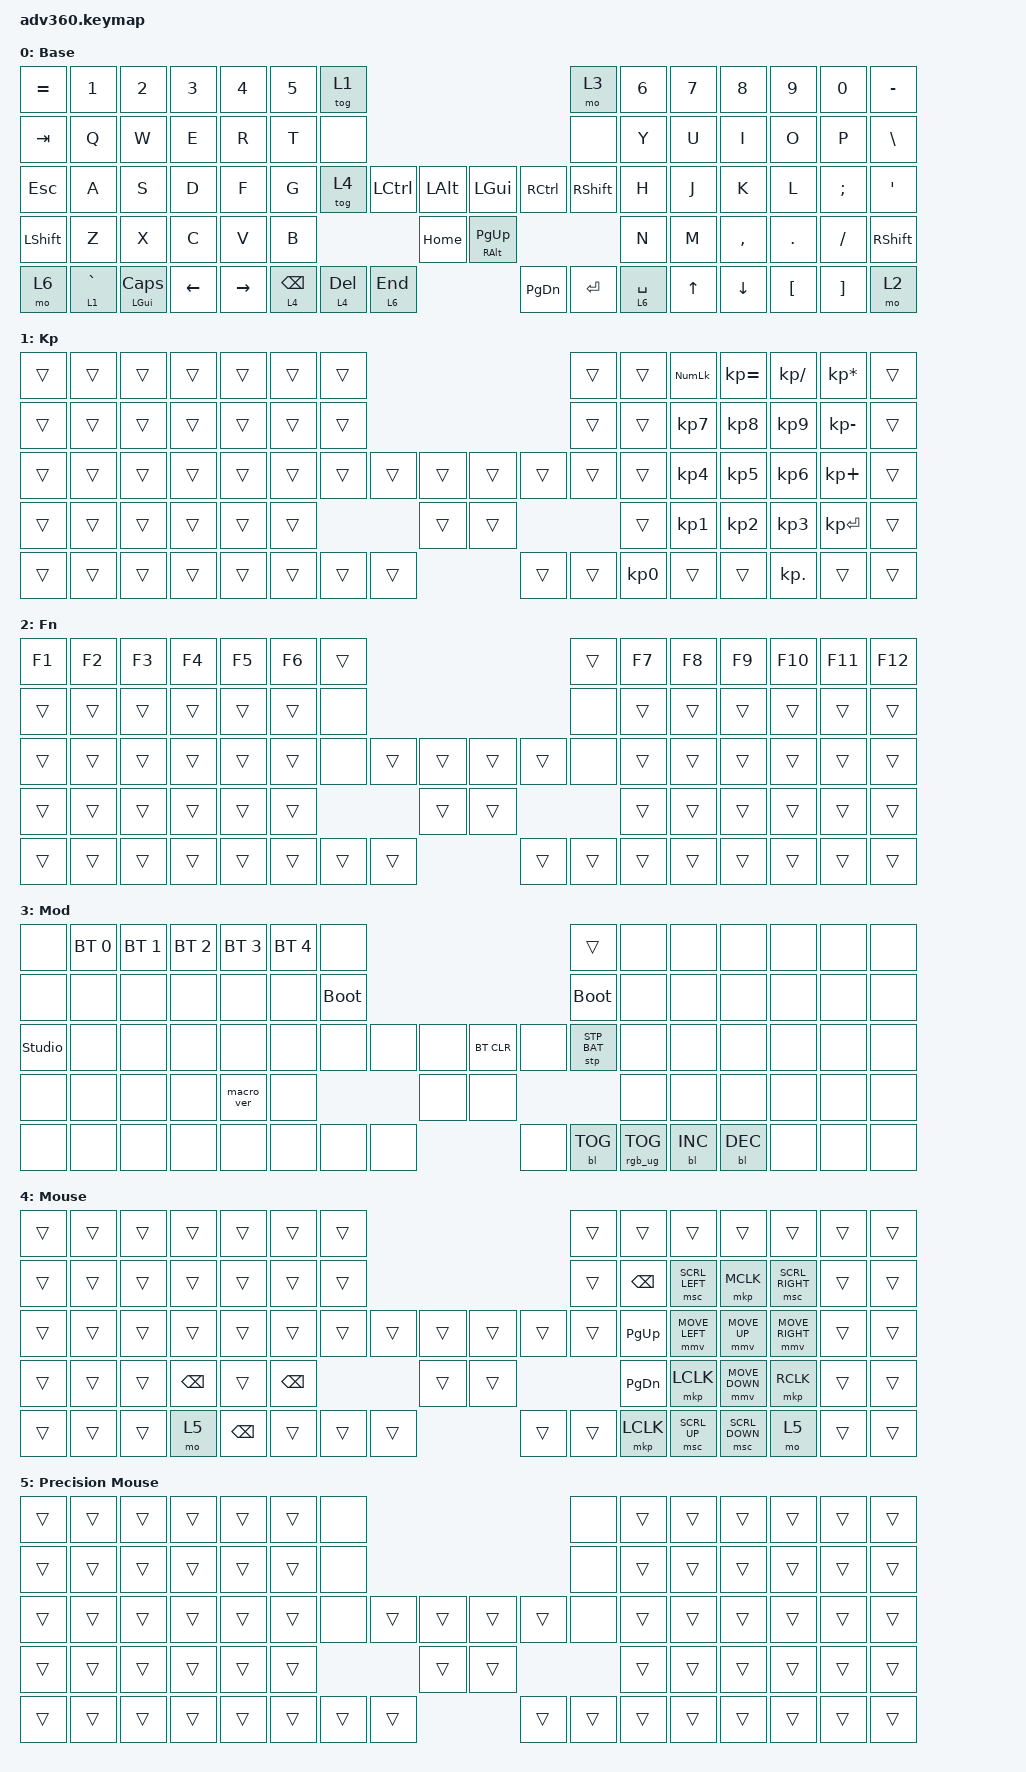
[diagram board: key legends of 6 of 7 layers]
#define ZMK_POINTING_DEFAULT_MOVE_VAL 1300  // default: 600
#define ZMK_POINTING_DEFAULT_SCRL_VAL 18    // default: 10

#include <input/processors.dtsi>

#include <behaviors.dtsi>
#include <dt-bindings/zmk/keys.h>
#include <dt-bindings/zmk/bt.h>
#include <dt-bindings/zmk/rgb.h>
#include <dt-bindings/zmk/stp.h>
#include <dt-bindings/zmk/backlight.h>
#include <dt-bindings/zmk/pointing.h>

/*
                                 ADVANTAGE 360 KEY MATRIX
 ╭────────────────────────────╮                           ╭────────────────────────────╮
 │  0   1   2   3   4   5   6 │                           │  7   8   9  10  11  12  13 │
 │ 14  15  16  17  18  19  20 │    ╭────────┬────────╮    │ 21  22  23  24  25  26  27 │
 │ 28  29  30  31  32  33  34 │╭───╯ 35  36 │ 37  38 ╰───╮│ 39  40  41  42  43  44  45 │
 │ 46  47  48  49  50  51 ╭───╯│ 65  66  67 │ 68  69  70 │╰───╮ 54  55  56  57  58  59 │
 │ 60  61  62  63  64 ╭───╯    ╰───────╮ 52 │ 53 ╭───────╯    ╰───╮ 71  72  73  74  75 │
 ╰────────────────────╯                ╰────┴────╯                ╰────────────────────╯
*/

#define KEYS_L 0 1 2  3  4  5  6 14 15 16 17 18 19 20 28 29 30 31 32 33 34 46 47 48 49 50 51 60 61 62 63 64  // Left-hand keys.
#define KEYS_R 7 8 9 10 11 12 13 21 22 23 24 25 26 27 39 40 41 42 43 44 45 54 55 56 57 58 59 71 72 73 74 74  // Right-hand keys.
#define THUMBS 35 36 37 38 65 66 67 68 69 70 52 53  // Thumb keys.

/ {
    zip_scroll_scaler: zip_scroll_scaler {
      compatible = "zmk,input-processor-scaler";
      #input-processor-cells = <2>;
      type = <INPUT_EV_REL>;
      codes = <INPUT_REL_WHEEL INPUT_REL_HWHEEL>;
      track-remainders; // TODO Try without this to see which feels better
    };
};

&lt {
  flavor = "balanced";
  tapping-term-ms = <175>; // This is the value already set by default
  quick-tap-ms = <125>;
};

// Override properties for mouse movement and scrolling
&mmv {
  time-to-max-speed-ms = <300>;
  acceleration-exponent = <1>;
};

&mmv_input_listener {
  precision {
    layers = <5>;
    input-processors = <&zip_xy_scaler 1 3>;
  };
};


&msc {
  time-to-max-speed-ms = <0>;
  acceleration-exponent = <0>;
  trigger-period-ms = <10>;
};

&msc_input_listener {
  precision {
    layers = <5>;
    input-processors = <&zip_scroll_scaler 1 2>;
  };
};


/ {

    behaviors {
      #include "macros.dtsi"
      #include "version.dtsi"

      hm: homerow_mods {
        compatible = "zmk,behavior-hold-tap";
        label = "HOMEROW_MODS";
        #binding-cells = <2>;
        tapping-term-ms = <200>;
        quick_tap_ms = <175>;
        flavor = "tap-preferred";
        bindings = <&kp>, <&kp>;
      };


      hml: home_row_mod_left {
        compatible = "zmk,behavior-hold-tap";
        #binding-cells = <2>;
        flavor = "balanced";
        require-prior-idle-ms = <150>;
        tapping-term-ms = <280>;
        quick-tap-ms = <175>;
        bindings = <&kp>, <&kp>;
        hold-trigger-key-positions = < KEYS_R >; // List of keys on the right side of the keyboard
        hold-trigger-on-release;
      };

      hmr: home_row_mod_right {
        compatible = "zmk,behavior-hold-tap";
        #binding-cells = <2>;
        flavor = "balanced";
        require-prior-idle-ms = <150>;
        tapping-term-ms = <280>;
        quick-tap-ms = <175>;
        bindings = <&kp>, <&kp>;
        hold-trigger-key-positions = < KEYS_L >; // List of keys on the left side of the keyboard
        hold-trigger-on-release;
      };
    };

  keymap {
    compatible = "zmk,keymap";

    default_layer {
      display-name = "Base";
      bindings = <
        &kp EQUAL &kp N1      &kp N2        &kp N3   &kp N4     &kp N5 &tog 1                                                               &mo 3      &kp N6 &kp N7 &kp N8    &kp N9   &kp N0   &kp MINUS
        &kp TAB   &kp Q       &kp W         &kp E    &kp R      &kp T  &none                                                                &none      &kp Y  &kp U  &kp I     &kp O    &kp P    &kp BSLH
        &kp ESC   &kp A       &kp S         &kp D    &kp F      &kp G  &tog 4          &kp LCTRL &kp LALT   &kp LGUI  &kp RCTRL             &kp RSHIFT &kp H  &kp J  &kp K     &kp L    &kp SEMI &kp SQT
        &kp LSHFT &kp Z       &kp X         &kp C    &kp V      &kp B                            &kp HOME   &hmr RALT PG_UP                            &kp N  &kp M  &kp COMMA &kp DOT  &kp FSLH &kp RSHFT
        &mo 6     &lt 1 GRAVE &mt LGUI CAPS &kp LEFT &kp RIGHT              &lt 4 BSPC &lt 4 DEL &lt 6 END  &kp PG_DN &kp ENTER &lt 6 SPACE                   &kp UP &kp DOWN  &kp LBKT &kp RBKT &mo 2
      >;
    };
    keypad {
      display-name = "Kp";
      bindings = <
        &trans &trans &trans &trans &trans &trans &trans                                           &trans &trans &kp KP_NUM &kp KP_EQUAL &kp KP_DIVIDE &kp KP_MULTIPLY  &trans
        &trans &trans &trans &trans &trans &trans &trans                                           &trans &trans &kp KP_N7  &kp KP_N8    &kp KP_N9     &kp KP_MINUS     &trans
        &trans &trans &trans &trans &trans &trans &trans        &trans &trans &trans &trans        &trans &trans &kp KP_N4  &kp KP_N5    &kp KP_N6     &kp KP_PLUS      &trans
        &trans &trans &trans &trans &trans &trans                      &trans &trans                      &trans &kp KP_N1  &kp KP_N2    &kp KP_N3     &kp KP_ENTER     &trans
        &trans &trans &trans &trans &trans               &trans &trans &trans &trans &trans &kp KP_N0            &trans     &trans       &kp KP_DOT    &trans           &trans
      >;
    };
    fn {
      display-name = "Fn";
      bindings = <
        &kp F1 &kp F2 &kp F3 &kp F4 &kp F5 &kp F6 &trans                                           &trans &kp F7 &kp F8 &kp F9 &kp F10 &kp F11 &kp F12
        &trans &trans &trans &trans &trans &trans  &none                                           &none  &trans &trans &trans &trans  &trans  &trans
        &trans &trans &trans &trans &trans &trans  &none        &trans &trans &trans &trans        &none  &trans &trans &trans &trans  &trans  &trans
        &trans &trans &trans &trans &trans &trans                      &trans &trans                      &trans &trans &trans &trans  &trans  &trans
        &trans &trans &trans &trans &trans               &trans &trans &trans &trans &trans &trans               &trans &trans &trans  &trans  &trans
      >;
    };
    mod {
      display-name = "Mod";
      bindings = <
        &none           &bt BT_SEL 0 &bt BT_SEL 1 &bt BT_SEL 2 &bt BT_SEL 3 &bt BT_SEL 4 &none                                                                &trans       &none        &none        &none        &none &none &none
        &none           &none        &none        &none        &none        &none        &bootloader                                                          &bootloader  &none        &none        &none        &none &none &none
        &studio_unlock  &none        &none        &none        &none        &none        &none              &none &none &bt BT_CLR &none                      &stp STP_BAT &none        &none        &none        &none &none &none
        &none &none     &none        &none        &macro_ver   &none                                              &none &none                                              &none        &none        &none        &none &none &none
        &none &none     &none        &none        &none                                               &none &none &none &none      &bl BL_TOG &rgb_ug RGB_TOG                           &bl BL_INC   &bl BL_DEC   &none &none &none
      >;
    };

    mouse {
      display-name = "Mouse";
      bindings = <
        &trans &trans &trans &trans   &trans &trans &trans                                           &trans &trans    &trans          &trans         &trans          &trans &trans
        &trans &trans &trans &trans   &trans &trans &trans                                           &trans &kp BSPC  &msc SCRL_LEFT  &mkp MCLK      &msc SCRL_RIGHT &trans &trans
        &trans &trans &trans &trans   &trans &trans &trans      &trans &trans &trans &trans          &trans &kp PG_UP &mmv MOVE_LEFT  &mmv MOVE_UP   &mmv MOVE_RIGHT &trans &trans
        &trans &trans &trans &kp BSPC &trans &kp BSPC                  &trans &trans                        &kp PG_DN &mkp LCLK       &mmv MOVE_DOWN &mkp RCLK       &trans &trans
        &trans &trans &trans &mo 5    &kp BSPC           &trans &trans &trans &trans &trans &mkp LCLK                 &msc SCRL_UP    &msc SCRL_DOWN &mo 5           &trans &trans
      >;
    };

    mouse_precise {
      display-name = "Precision Mouse";
      bindings = <
        &trans &trans &trans &trans &trans &trans  &none                                           &none  &trans &trans &trans &trans  &trans  &trans
        &trans &trans &trans &trans &trans &trans  &none                                           &none  &trans &trans &trans &trans  &trans  &trans
        &trans &trans &trans &trans &trans &trans  &none        &trans &trans &trans &trans        &none  &trans &trans &trans &trans  &trans  &trans
        &trans &trans &trans &trans &trans &trans                      &trans &trans                      &trans &trans &trans &trans  &trans  &trans
        &trans &trans &trans &trans &trans               &trans &trans &trans &trans &trans &trans               &trans &trans &trans  &trans  &trans
      >;
    };

    ergo {
      display-name = "Ergo";
      bindings = <
        &trans &trans &trans &trans   &trans &trans &trans                                           &trans &trans    &trans    &trans     &trans     &trans    &trans
        &trans &trans &trans &trans   &trans &trans &trans                                           &trans &trans    &kp RCTRL &kp SQT    &kp BSLH   &trans    &trans
        &trans &trans &trans &trans   &trans &trans &trans        &trans &trans &trans &trans        &trans &trans    &kp LALT  &kp RSHIFT &kp RGUI   &trans    &trans
        &trans &trans &trans &trans   &trans &trans                      &trans &trans                      &kp SPACE &kp P     &kp MINUS  &kp SPACE  &trans    &trans
        &trans &trans &trans &trans   &trans               &trans &trans &trans &trans &trans &trans                  &kp PG_UP &kp PG_DN  &kp EQUAL
      >;
    };


    extra4 {
      display-name = "Yellow";
      status = "reserved";
    };
  };
};
